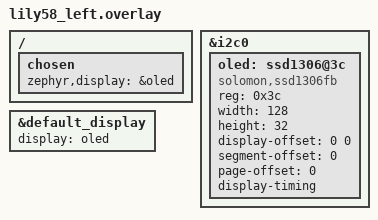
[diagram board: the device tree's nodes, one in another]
/* Start with the I2C bus definition first */
&i2c0 {
    status = "okay";

    oled: ssd1306@3c { 
        compatible = "solomon,ssd1306fb";
        reg = <0x3c>;
        width = <128>;
        height = <32>;
        display-offset = <0 0>;
        segment-offset = <0>;
        page-offset = <0>;
        display-timing;
    };
};

/* Now reference the defined device in the display alias nodes */
/ {
    chosen {
        zephyr,display = &oled;
    };
};

&default_display {
    status = "okay";
    display = <&oled>;
};
